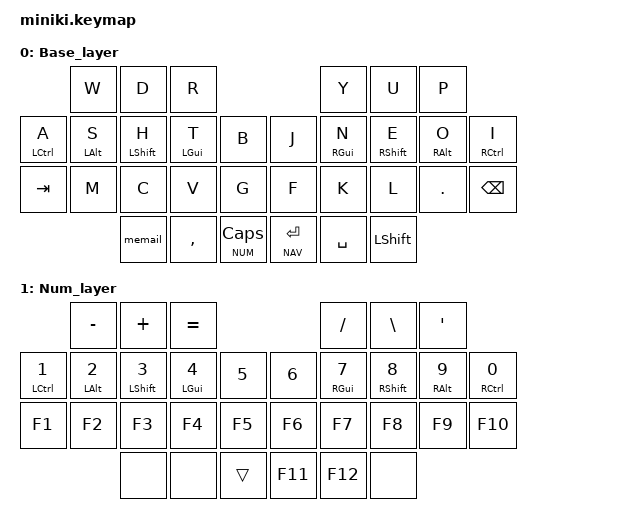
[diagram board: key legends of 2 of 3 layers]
#include <behaviors.dtsi>
#include <dt-bindings/zmk/keys.h>
#include <dt-bindings/zmk/bt.h>

#define BASE 0
#define NUM 1
#define NAV 2

/ {
  macros {

    memail: memail {
          display-name = "memail";
          compatible = "zmk,behavior-macro";
          #binding-cells = <0>;
          bindings
            = <&macro_tap &kp J>
            , <&macro_tap &kp A>
            , <&macro_tap &kp N>
            , <&macro_tap &kp P>
            , <&macro_tap &kp E>
            , <&macro_tap &kp T>
            , <&macro_tap &kp E>
            , <&macro_tap &kp R>
            , <&macro_press &kp LSHFT>
            , <&macro_tap &kp NUMBER_2>
            , <&macro_release &kp LSHFT>
            , <&macro_tap &kp T>
            , <&macro_tap &kp A>
            , <&macro_tap &kp M>
            , <&macro_tap &kp M>
            , <&macro_tap &kp I>
            , <&macro_tap &kp N>
            , <&macro_tap &kp G>
            , <&macro_tap &kp A>
            , <&macro_tap &kp S>
            , <&macro_tap &kp DOT>
            , <&macro_tap &kp N>
            , <&macro_tap &kp L>;
        };
  };

  combos {
    compatible = "zmk,combos";

    combo_CAPS {
      timeout-ms = <50>;
      key-positions = <11 21>;
      layers = <BASE>;
      bindings = <&kp CAPS>;
    };

    combo_INS {
      timeout-ms = <50>;
      key-positions = <15 25>;
      layers = <BASE>;
      bindings = <&kp INS>;
    };

    combo_DEL {
      timeout-ms = <50>;
      key-positions = <24 25>;
      layers = <BASE>;
      bindings = <&kp DEL>;
    };

    combo_Q {
      timeout-ms = <50>;
      key-positions = <0 1>;
      layers = <BASE>;
      bindings = <&kp Q>;
    };

    combo_ESC {
      timeout-ms = <50>;
      key-positions = <6 16>;
      layers = <BASE>;
      bindings = <&kp ESC>;
    };

    combo_Z {
      timeout-ms = <50>;
      key-positions = <17 18>;
      layers = <BASE>;
      bindings = <&kp Z>;
    };

    combo_X {
      timeout-ms = <50>;
      key-positions = <18 19>;
      layers = <BASE>;
      bindings = <&kp X>;
    };

    combo_BTCLR {
      timeout-ms = <50>;
      key-positions = <6 20>;
      layers = <BASE>;
      bindings = <&bt BT_CLR>;
    };

    combo_BT1 {
      timeout-ms = <50>;
      key-positions = <0 17>;
      layers = <BASE>;
      bindings = <&bt BT_SEL 1>;
    };

    combo_BT2 {
      timeout-ms = <50>;
      key-positions = <1 18>;
      layers = <BASE>;
      bindings = <&bt BT_SEL 2>;
    };

    combo_BT3 {
      timeout-ms = <50>;
      key-positions = <2 19>;
      layers = <BASE>;
      bindings = <&bt BT_SEL 3>;
    };
  };


  behaviors {
    hm: homerow_mods {
      compatible = "zmk,behavior-hold-tap";
      #binding-cells = <2>;
      tapping-term-ms = <250>;
      flavor = "tap-preferred";
      bindings = <&kp>, <&kp>;
    };
  };

  keymap {
    compatible = "zmk,keymap";

    Base_layer {
      bindings = <
                    &kp W       &kp D        &kp R                                             &kp Y        &kp U         &kp P
        &hm LCTRL A &hm LALT S  &hm LSHFT H  &hm LGUI T   &kp B              &kp J             &hm RGUI N   &hm RSHFT E   &hm RALT O   &hm RCTRL I
        &kp TAB     &kp M       &kp C        &kp V        &kp G              &kp F             &kp K        &kp L         &kp DOT      &kp BACKSPACE
                                &memail      &kp COMMA    &lt NUM CAPS       &lt NAV RETURN    &kp SPACE    &kp LSHFT
      >;
    };

    Num_layer {
          bindings = <
                                &kp MINUS          &kp PLUS            &kp EQUAL                                          &kp SLASH          &kp BACKSLASH       &kp SINGLE_QUOTE
            &hm LCTRL NUMBER_1  &hm LALT NUMBER_2  &hm LSHFT NUMBER_3  &hm LGUI NUMBER_4  &kp NUMBER_5      &kp NUMBER_6  &hm RGUI NUMBER_7  &hm RSHFT NUMBER_8  &hm RALT NUMBER_9  &hm RCTRL NUMBER_0
            &kp F1              &kp F2             &kp F3              &kp F4             &kp F5            &kp F6        &kp F7             &kp F8              &kp F9             &kp F10
                                                   &none               &none              &trans            &kp F11       &kp F12            &none
          >;
        };

    Nav_layer {
      bindings = <
                      &kp GRAVE              &none                       &none                                               &kp HOME         &kp UP           &kp END
        &hm LCTRL LT  &hm LALT LEFT_BRACKET  &hm LSHFT LEFT_PARENTHESIS  &hm LGUI LEFT_BRACE  &none               &kp LG(V)  &hm RGUI LEFT    &hm RSHFT DOWN   &hm RALT RIGHT   &hm RCTRL PG_UP
        &kp GT        &kp RIGHT_BRACKET      &kp RIGHT_PARENTHESIS       &kp RIGHT_BRACE      &kp SEMICOLON       &kp LG(C)  &kp LG(X)        &kp LG(Z)        &kp LG(LS(Z))    &kp PG_DN
                                             &kp TILDE                   &none                &kp LG(LA(ESC))     &trans     &kp PRINTSCREEN  &none            &none
      >;
    };
  };
};
